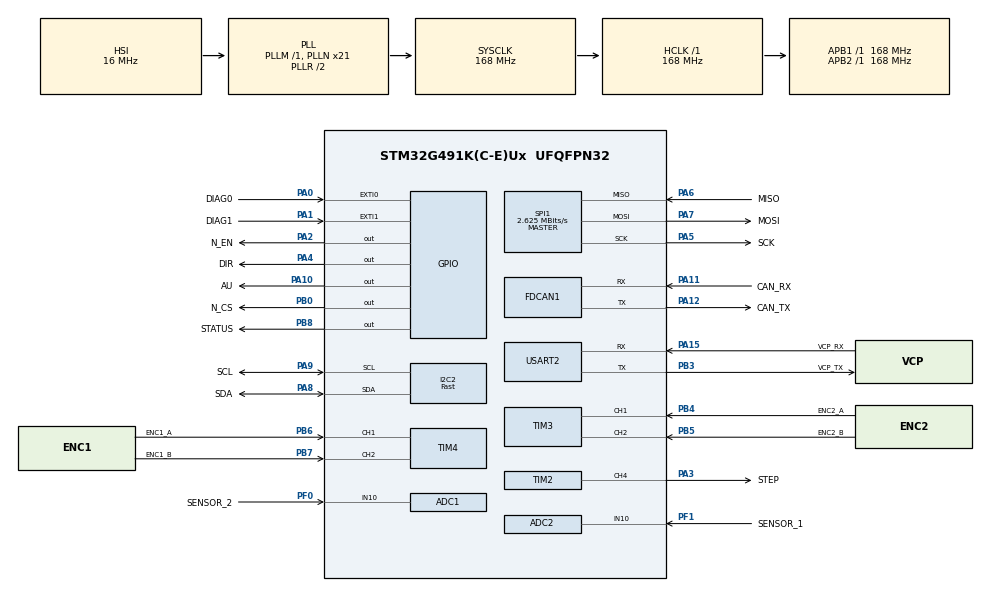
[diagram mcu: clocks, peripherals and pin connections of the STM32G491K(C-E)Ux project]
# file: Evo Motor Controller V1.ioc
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ADC1.Channel-0\#ChannelRegularConversion=ADC_CHANNEL_10
ADC1.NbrOfConversionFlag=1
ADC1.OffsetNumber-0\#ChannelRegularConversion=ADC_OFFSET_NONE
ADC1.Rank-0\#ChannelRegularConversion=1
ADC1.SamplingTime-0\#ChannelRegularConversion=ADC_SAMPLETIME_2CYCLES_5
ADC1.master=1
ADC2.Channel-0\#ChannelRegularConversion=ADC_CHANNEL_10
ADC2.NbrOfConversionFlag=1
ADC2.OffsetNumber-0\#ChannelRegularConversion=ADC_OFFSET_NONE
ADC2.Rank-0\#ChannelRegularConversion=1
ADC2.SamplingTime-0\#ChannelRegularConversion=ADC_SAMPLETIME_2CYCLES_5
FDCAN1.CalculateBaudRateNominal=2100000
FDCAN1.CalculateTimeBitNominal=476
FDCAN1.CalculateTimeQuantumNominal=95.23809523809524
I2C2.I2C_Speed_Mode=I2C_Fast
I2C2.Timing=0x20B21E5A
Mcu.Family=STM32G4
Mcu.Name=STM32G491K(C-E)Ux
Mcu.Package=UFQFPN32
NVIC.I2C2_ER_IRQn=true\:0\:0\:false\:false\:true\:true\:true\:true
NVIC.I2C2_EV_IRQn=true\:0\:0\:false\:false\:true\:true\:true\:true
NVIC.PriorityGroup=NVIC_PRIORITYGROUP_4
PA0.GPIO_Label=DIAG0
PA0.Signal=GPXTI0
PA1.GPIO_Label=DIAG1
PA1.Signal=GPXTI1
PA10.GPIO_Label=AU
PA10.Signal=GPIO_Output
PA11.GPIO_Label=CAN_RX
PA11.Mode=FDCAN_Activate
PA11.Signal=FDCAN1_RX
PA12.GPIO_Label=CAN_TX
PA12.Mode=FDCAN_Activate
PA12.Signal=FDCAN1_TX
PA13.GPIO_Label=SWDIO
PA13.Mode=Serial_Wire
PA13.Signal=SYS_JTMS-SWDIO
PA14.GPIO_Label=SWCLK
PA14.Mode=Serial_Wire
PA14.Signal=SYS_JTCK-SWCLK
PA15.GPIO_Label=VCP_RX
PA15.Mode=Asynchronous
PA15.Signal=USART2_RX
PA2.GPIO_Label=N_EN
PA2.Signal=GPIO_Output
PA3.GPIO_Label=STEP
PA3.Signal=S_TIM2_CH4
PA4.GPIO_Label=DIR
PA4.Signal=GPIO_Output
PA5.GPIO_Label=SCK
PA5.Mode=Full_Duplex_Master
PA5.Signal=SPI1_SCK
PA6.GPIO_Label=MISO
PA6.Mode=Full_Duplex_Master
PA6.Signal=SPI1_MISO
PA7.GPIO_Label=MOSI
PA7.Mode=Full_Duplex_Master
PA7.Signal=SPI1_MOSI
PA8.GPIO_Label=SDA
PA8.Mode=I2C
PA8.Signal=I2C2_SDA
PA9.GPIO_Label=SCL
PA9.Mode=I2C
PA9.Signal=I2C2_SCL
PB0.GPIO_Label=N_CS
PB0.Signal=GPIO_Output
PB3.GPIO_Label=VCP_TX
PB3.Mode=Asynchronous
PB3.Signal=USART2_TX
PB4.GPIO_Label=ENC2_A
PB4.Signal=S_TIM3_CH1
PB5.GPIO_Label=ENC2_B
PB5.Signal=S_TIM3_CH2
PB6.GPIO_Label=ENC1_A
PB6.Signal=S_TIM4_CH1
PB7.GPIO_Label=ENC1_B
PB7.Signal=S_TIM4_CH2
PB8-BOOT0.GPIO_Label=STATUS
PB8-BOOT0.Signal=GPIO_Output
PF0-OSC_IN.GPIO_Label=SENSOR_2
PF0-OSC_IN.Mode=IN10-Single-Ended
PF0-OSC_IN.Signal=ADC1_IN10
PF1-OSC_OUT.GPIO_Label=SENSOR_1
PF1-OSC_OUT.Mode=IN10-Single-Ended
PF1-OSC_OUT.Signal=ADC2_IN10
ProjectManager.HeapSize=0x200
ProjectManager.StackSize=0x400
ProjectManager.TargetToolchain=STM32CubeIDE
RCC.ADC12Freq_Value=168000000
RCC.ADC345Freq_Value=168000000
RCC.AHBFreq_Value=168000000
RCC.APB1Freq_Value=168000000
RCC.APB1TimFreq_Value=168000000
RCC.APB2Freq_Value=168000000
RCC.APB2TimFreq_Value=168000000
RCC.CortexFreq_Value=168000000
RCC.EXTERNAL_CLOCK_VALUE=12288000
RCC.HCLKFreq_Value=168000000
RCC.HSE_VALUE=8000000
RCC.HSI48_VALUE=48000000
RCC.HSI_VALUE=16000000
RCC.LSE_VALUE=32768
RCC.PLLN=21
RCC.SYSCLKFreq_VALUE=168000000
RCC.SYSCLKSource=RCC_SYSCLKSOURCE_PLLCLK
RCC.VCOOutputFreq_Value=336000000
SH.S_TIM2_CH4.0=TIM2_CH4,PWM Generation4 CH4
SH.S_TIM3_CH1.0=TIM3_CH1,Encoder_Interface
SH.S_TIM3_CH2.0=TIM3_CH2,Encoder_Interface
SH.S_TIM4_CH1.0=TIM4_CH1,Encoder_Interface
SH.S_TIM4_CH2.0=TIM4_CH2,Encoder_Interface
SPI1.BaudRatePrescaler=SPI_BAUDRATEPRESCALER_64
SPI1.CLKPhase=SPI_PHASE_2EDGE
SPI1.CLKPolarity=SPI_POLARITY_HIGH
SPI1.CalculateBaudRate=2.625 MBits/s
SPI1.DataSize=SPI_DATASIZE_8BIT
SPI1.Direction=SPI_DIRECTION_2LINES
SPI1.Mode=SPI_MODE_MASTER
SPI1.VirtualType=VM_MASTER
TIM2.Channel-PWM\ Generation4\ CH4=TIM_CHANNEL_4
USART2.VirtualMode-Asynchronous=VM_ASYNC
VP_SYS_VS_DBSignals.Mode=DisableDeadBatterySignals
board=custom

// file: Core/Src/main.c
/* USER CODE BEGIN Header */
/**
  ******************************************************************************
  * @file           : main.c
  * @brief          : Main program body
  ******************************************************************************
  * @attention
  *
  * Copyright (c) 2025 STMicroelectronics.
  * All rights reserved.
  *
  * This software is licensed under terms that can be found in the LICENSE file
  * in the root directory of this software component.
  * If no LICENSE file comes with this software, it is provided AS-IS.
  *
  ******************************************************************************
  */
/* USER CODE END Header */
#include "main.h"

/* USER CODE BEGIN Includes */
#include <stdio.h>

#include "runtime.h"
/* USER CODE END Includes */

ADC_HandleTypeDef hadc1;
ADC_HandleTypeDef hadc2;

FDCAN_HandleTypeDef hfdcan1;

I2C_HandleTypeDef hi2c2;

SPI_HandleTypeDef hspi1;

TIM_HandleTypeDef htim2;
TIM_HandleTypeDef htim3;
TIM_HandleTypeDef htim4;

UART_HandleTypeDef huart2;

void SystemClock_Config(void);
static void MX_GPIO_Init(void);
static void MX_ADC1_Init(void);
static void MX_ADC2_Init(void);
static void MX_SPI1_Init(void);
static void MX_TIM2_Init(void);
static void MX_TIM4_Init(void);
static void MX_USART2_UART_Init(void);
static void MX_FDCAN1_Init(void);
static void MX_I2C2_Init(void);
static void MX_TIM3_Init(void);

/* USER CODE BEGIN 0 */
uint8_t __io_putchar(char ch){
	HAL_UART_Transmit(&huart2, (uint8_t*)&ch, 1, HAL_MAX_DELAY);
	return ch;
}
uint8_t __io_getchar(char ch){
    return HAL_UART_Transmit(&huart2, (uint8_t*)&ch, 1, HAL_MAX_DELAY);

}
/* USER CODE END 0 */

int main(void)
{

  /* MCU Configuration--------------------------------------------------------*/

  /* Reset of all peripherals, Initializes the Flash interface and the Systick. */
  HAL_Init();

  /* Configure the system clock */
  SystemClock_Config();

  /* Initialize all configured peripherals */
  MX_GPIO_Init();
  MX_ADC1_Init();
  MX_ADC2_Init();
  MX_SPI1_Init();
  MX_TIM2_Init();
  MX_TIM4_Init();
  MX_USART2_UART_Init();
  MX_FDCAN1_Init();
  MX_I2C2_Init();
  MX_TIM3_Init();
  /* USER CODE BEGIN 2 */
  printf("HAL init done ... \n");
  setup();
  printf("User init done ... \n");
  /* USER CODE END 2 */

  /* Infinite loop */
  /* USER CODE BEGIN WHILE */
  while (1)
  {
	  loop();
    /* USER CODE END WHILE */

  }
}

void SystemClock_Config(void)
{
  RCC_OscInitTypeDef RCC_OscInitStruct = {0};
  RCC_ClkInitTypeDef RCC_ClkInitStruct = {0};

  /** Configure the main internal regulator output voltage
  */
  HAL_PWREx_ControlVoltageScaling(PWR_REGULATOR_VOLTAGE_SCALE1_BOOST);

  /** Initializes the RCC Oscillators according to the specified parameters
  * in the RCC_OscInitTypeDef structure.
  */
  RCC_OscInitStruct.OscillatorType = RCC_OSCILLATORTYPE_HSI;
  RCC_OscInitStruct.HSIState = RCC_HSI_ON;
  RCC_OscInitStruct.HSICalibrationValue = RCC_HSICALIBRATION_DEFAULT;
  RCC_OscInitStruct.PLL.PLLState = RCC_PLL_ON;
  RCC_OscInitStruct.PLL.PLLSource = RCC_PLLSOURCE_HSI;
  RCC_OscInitStruct.PLL.PLLM = RCC_PLLM_DIV1;
  RCC_OscInitStruct.PLL.PLLN = 21;
  RCC_OscInitStruct.PLL.PLLP = RCC_PLLP_DIV2;
  RCC_OscInitStruct.PLL.PLLQ = RCC_PLLQ_DIV2;
  RCC_OscInitStruct.PLL.PLLR = RCC_PLLR_DIV2;
  if (HAL_RCC_OscConfig(&RCC_OscInitStruct) != HAL_OK)
  {
    Error_Handler();
  }

  /** Initializes the CPU, AHB and APB buses clocks
  */
  RCC_ClkInitStruct.ClockType = RCC_CLOCKTYPE_HCLK|RCC_CLOCKTYPE_SYSCLK
                              |RCC_CLOCKTYPE_PCLK1|RCC_CLOCKTYPE_PCLK2;
  RCC_ClkInitStruct.SYSCLKSource = RCC_SYSCLKSOURCE_PLLCLK;
  RCC_ClkInitStruct.AHBCLKDivider = RCC_SYSCLK_DIV1;
  RCC_ClkInitStruct.APB1CLKDivider = RCC_HCLK_DIV1;
  RCC_ClkInitStruct.APB2CLKDivider = RCC_HCLK_DIV1;

  if (HAL_RCC_ClockConfig(&RCC_ClkInitStruct, FLASH_LATENCY_4) != HAL_OK)
  {
    Error_Handler();
  }
}

static void MX_ADC1_Init(void)
{

  ADC_MultiModeTypeDef multimode = {0};
  ADC_ChannelConfTypeDef sConfig = {0};

  /** Common config
  */
  hadc1.Instance = ADC1;
  hadc1.Init.ClockPrescaler = ADC_CLOCK_SYNC_PCLK_DIV4;
  hadc1.Init.Resolution = ADC_RESOLUTION_12B;
  hadc1.Init.DataAlign = ADC_DATAALIGN_RIGHT;
  hadc1.Init.GainCompensation = 0;
  hadc1.Init.ScanConvMode = ADC_SCAN_DISABLE;
  hadc1.Init.EOCSelection = ADC_EOC_SINGLE_CONV;
  hadc1.Init.LowPowerAutoWait = DISABLE;
  hadc1.Init.ContinuousConvMode = DISABLE;
  hadc1.Init.NbrOfConversion = 1;
  hadc1.Init.DiscontinuousConvMode = DISABLE;
  hadc1.Init.ExternalTrigConv = ADC_SOFTWARE_START;
  hadc1.Init.ExternalTrigConvEdge = ADC_EXTERNALTRIGCONVEDGE_NONE;
  hadc1.Init.DMAContinuousRequests = DISABLE;
  hadc1.Init.Overrun = ADC_OVR_DATA_PRESERVED;
  hadc1.Init.OversamplingMode = DISABLE;
  if (HAL_ADC_Init(&hadc1) != HAL_OK)
  {
    Error_Handler();
  }

  /** Configure the ADC multi-mode
  */
  multimode.Mode = ADC_MODE_INDEPENDENT;
  if (HAL_ADCEx_MultiModeConfigChannel(&hadc1, &multimode) != HAL_OK)
  {
    Error_Handler();
  }

  /** Configure Regular Channel
  */
  sConfig.Channel = ADC_CHANNEL_10;
  sConfig.Rank = ADC_REGULAR_RANK_1;
  sConfig.SamplingTime = ADC_SAMPLETIME_2CYCLES_5;
  sConfig.SingleDiff = ADC_SINGLE_ENDED;
  sConfig.OffsetNumber = ADC_OFFSET_NONE;
  sConfig.Offset = 0;
  if (HAL_ADC_ConfigChannel(&hadc1, &sConfig) != HAL_OK)
  {
    Error_Handler();
  }

}

static void MX_ADC2_Init(void)
{

  ADC_ChannelConfTypeDef sConfig = {0};

  /** Common config
  */
  hadc2.Instance = ADC2;
  hadc2.Init.ClockPrescaler = ADC_CLOCK_SYNC_PCLK_DIV4;
  hadc2.Init.Resolution = ADC_RESOLUTION_12B;
  hadc2.Init.DataAlign = ADC_DATAALIGN_RIGHT;
  hadc2.Init.GainCompensation = 0;
  hadc2.Init.ScanConvMode = ADC_SCAN_DISABLE;
  hadc2.Init.EOCSelection = ADC_EOC_SINGLE_CONV;
  hadc2.Init.LowPowerAutoWait = DISABLE;
  hadc2.Init.ContinuousConvMode = DISABLE;
  hadc2.Init.NbrOfConversion = 1;
  hadc2.Init.DiscontinuousConvMode = DISABLE;
  hadc2.Init.ExternalTrigConv = ADC_SOFTWARE_START;
  hadc2.Init.ExternalTrigConvEdge = ADC_EXTERNALTRIGCONVEDGE_NONE;
  hadc2.Init.DMAContinuousRequests = DISABLE;
  hadc2.Init.Overrun = ADC_OVR_DATA_PRESERVED;
  hadc2.Init.OversamplingMode = DISABLE;
  if (HAL_ADC_Init(&hadc2) != HAL_OK)
  {
    Error_Handler();
  }

  /** Configure Regular Channel
  */
  sConfig.Channel = ADC_CHANNEL_10;
  sConfig.Rank = ADC_REGULAR_RANK_1;
  sConfig.SamplingTime = ADC_SAMPLETIME_2CYCLES_5;
  sConfig.SingleDiff = ADC_SINGLE_ENDED;
  sConfig.OffsetNumber = ADC_OFFSET_NONE;
  sConfig.Offset = 0;
  if (HAL_ADC_ConfigChannel(&hadc2, &sConfig) != HAL_OK)
  {
    Error_Handler();
  }

}

static void MX_FDCAN1_Init(void)
{

  hfdcan1.Instance = FDCAN1;
  hfdcan1.Init.ClockDivider = FDCAN_CLOCK_DIV1;
  hfdcan1.Init.FrameFormat = FDCAN_FRAME_CLASSIC;
  hfdcan1.Init.Mode = FDCAN_MODE_NORMAL;
  hfdcan1.Init.AutoRetransmission = DISABLE;
  hfdcan1.Init.TransmitPause = DISABLE;
  hfdcan1.Init.ProtocolException = DISABLE;
  hfdcan1.Init.NominalPrescaler = 16;
  hfdcan1.Init.NominalSyncJumpWidth = 1;
  hfdcan1.Init.NominalTimeSeg1 = 2;
  hfdcan1.Init.NominalTimeSeg2 = 2;
  hfdcan1.Init.DataPrescaler = 1;
  hfdcan1.Init.DataSyncJumpWidth = 1;
  hfdcan1.Init.DataTimeSeg1 = 1;
  hfdcan1.Init.DataTimeSeg2 = 1;
  hfdcan1.Init.StdFiltersNbr = 0;
  hfdcan1.Init.ExtFiltersNbr = 0;
  hfdcan1.Init.TxFifoQueueMode = FDCAN_TX_FIFO_OPERATION;
  if (HAL_FDCAN_Init(&hfdcan1) != HAL_OK)
  {
    Error_Handler();
  }

}

static void MX_I2C2_Init(void)
{

  hi2c2.Instance = I2C2;
  hi2c2.Init.Timing = 0x20B21E5A;
  hi2c2.Init.OwnAddress1 = 0;
  hi2c2.Init.AddressingMode = I2C_ADDRESSINGMODE_7BIT;
  hi2c2.Init.DualAddressMode = I2C_DUALADDRESS_DISABLE;
  hi2c2.Init.OwnAddress2 = 0;
  hi2c2.Init.OwnAddress2Masks = I2C_OA2_NOMASK;
  hi2c2.Init.GeneralCallMode = I2C_GENERALCALL_DISABLE;
  hi2c2.Init.NoStretchMode = I2C_NOSTRETCH_DISABLE;
  if (HAL_I2C_Init(&hi2c2) != HAL_OK)
  {
    Error_Handler();
  }

  /** Configure Analogue filter
  */
  if (HAL_I2CEx_ConfigAnalogFilter(&hi2c2, I2C_ANALOGFILTER_ENABLE) != HAL_OK)
  {
    Error_Handler();
  }

  /** Configure Digital filter
  */
  if (HAL_I2CEx_ConfigDigitalFilter(&hi2c2, 0) != HAL_OK)
  {
    Error_Handler();
  }

}

static void MX_SPI1_Init(void)
{

  /* SPI1 parameter configuration*/
  hspi1.Instance = SPI1;
  hspi1.Init.Mode = SPI_MODE_MASTER;
  hspi1.Init.Direction = SPI_DIRECTION_2LINES;
  hspi1.Init.DataSize = SPI_DATASIZE_8BIT;
  hspi1.Init.CLKPolarity = SPI_POLARITY_HIGH;
  hspi1.Init.CLKPhase = SPI_PHASE_2EDGE;
  hspi1.Init.NSS = SPI_NSS_SOFT;
  hspi1.Init.BaudRatePrescaler = SPI_BAUDRATEPRESCALER_64;
  hspi1.Init.FirstBit = SPI_FIRSTBIT_MSB;
  hspi1.Init.TIMode = SPI_TIMODE_DISABLE;
  hspi1.Init.CRCCalculation = SPI_CRCCALCULATION_DISABLE;
  hspi1.Init.CRCPolynomial = 7;
  hspi1.Init.CRCLength = SPI_CRC_LENGTH_DATASIZE;
  hspi1.Init.NSSPMode = SPI_NSS_PULSE_DISABLE;
  if (HAL_SPI_Init(&hspi1) != HAL_OK)
  {
    Error_Handler();
  }

}

static void MX_TIM2_Init(void)
{

  TIM_MasterConfigTypeDef sMasterConfig = {0};
  TIM_OC_InitTypeDef sConfigOC = {0};

  htim2.Instance = TIM2;
  htim2.Init.Prescaler = 0;
  htim2.Init.CounterMode = TIM_COUNTERMODE_UP;
  htim2.Init.Period = 4294967295;
  htim2.Init.ClockDivision = TIM_CLOCKDIVISION_DIV1;
  htim2.Init.AutoReloadPreload = TIM_AUTORELOAD_PRELOAD_DISABLE;
  if (HAL_TIM_PWM_Init(&htim2) != HAL_OK)
  {
    Error_Handler();
  }
  sMasterConfig.MasterOutputTrigger = TIM_TRGO_RESET;
  sMasterConfig.MasterSlaveMode = TIM_MASTERSLAVEMODE_DISABLE;
  if (HAL_TIMEx_MasterConfigSynchronization(&htim2, &sMasterConfig) != HAL_OK)
  {
    Error_Handler();
  }
  sConfigOC.OCMode = TIM_OCMODE_PWM1;
  sConfigOC.Pulse = 0;
  sConfigOC.OCPolarity = TIM_OCPOLARITY_HIGH;
  sConfigOC.OCFastMode = TIM_OCFAST_DISABLE;
  if (HAL_TIM_PWM_ConfigChannel(&htim2, &sConfigOC, TIM_CHANNEL_4) != HAL_OK)
  {
    Error_Handler();
  }
  HAL_TIM_MspPostInit(&htim2);

}

static void MX_TIM3_Init(void)
{

  TIM_Encoder_InitTypeDef sConfig = {0};
  TIM_MasterConfigTypeDef sMasterConfig = {0};

  htim3.Instance = TIM3;
  htim3.Init.Prescaler = 0;
  htim3.Init.CounterMode = TIM_COUNTERMODE_UP;
  htim3.Init.Period = 65535;
  htim3.Init.ClockDivision = TIM_CLOCKDIVISION_DIV1;
  htim3.Init.AutoReloadPreload = TIM_AUTORELOAD_PRELOAD_DISABLE;
  sConfig.EncoderMode = TIM_ENCODERMODE_TI1;
  sConfig.IC1Polarity = TIM_ICPOLARITY_RISING;
  sConfig.IC1Selection = TIM_ICSELECTION_DIRECTTI;
  sConfig.IC1Prescaler = TIM_ICPSC_DIV1;
  sConfig.IC1Filter = 0;
  sConfig.IC2Polarity = TIM_ICPOLARITY_RISING;
  sConfig.IC2Selection = TIM_ICSELECTION_DIRECTTI;
  sConfig.IC2Prescaler = TIM_ICPSC_DIV1;
  sConfig.IC2Filter = 0;
  if (HAL_TIM_Encoder_Init(&htim3, &sConfig) != HAL_OK)
  {
    Error_Handler();
  }
  sMasterConfig.MasterOutputTrigger = TIM_TRGO_RESET;
  sMasterConfig.MasterSlaveMode = TIM_MASTERSLAVEMODE_DISABLE;
  if (HAL_TIMEx_MasterConfigSynchronization(&htim3, &sMasterConfig) != HAL_OK)
  {
    Error_Handler();
  }

}

static void MX_TIM4_Init(void)
{

  TIM_Encoder_InitTypeDef sConfig = {0};
  TIM_MasterConfigTypeDef sMasterConfig = {0};

  htim4.Instance = TIM4;
  htim4.Init.Prescaler = 0;
  htim4.Init.CounterMode = TIM_COUNTERMODE_UP;
  htim4.Init.Period = 65535;
  htim4.Init.ClockDivision = TIM_CLOCKDIVISION_DIV1;
  htim4.Init.AutoReloadPreload = TIM_AUTORELOAD_PRELOAD_DISABLE;
  sConfig.EncoderMode = TIM_ENCODERMODE_TI1;
  sConfig.IC1Polarity = TIM_ICPOLARITY_RISING;
  sConfig.IC1Selection = TIM_ICSELECTION_DIRECTTI;
  sConfig.IC1Prescaler = TIM_ICPSC_DIV1;
  sConfig.IC1Filter = 0;
  sConfig.IC2Polarity = TIM_ICPOLARITY_RISING;
  sConfig.IC2Selection = TIM_ICSELECTION_DIRECTTI;
  sConfig.IC2Prescaler = TIM_ICPSC_DIV1;
  sConfig.IC2Filter = 0;
  if (HAL_TIM_Encoder_Init(&htim4, &sConfig) != HAL_OK)
  {
    Error_Handler();
  }
  sMasterConfig.MasterOutputTrigger = TIM_TRGO_RESET;
  sMasterConfig.MasterSlaveMode = TIM_MASTERSLAVEMODE_DISABLE;
  if (HAL_TIMEx_MasterConfigSynchronization(&htim4, &sMasterConfig) != HAL_OK)
  {
    Error_Handler();
  }

}

static void MX_USART2_UART_Init(void)
{

  huart2.Instance = USART2;
  huart2.Init.BaudRate = 115200;
  huart2.Init.WordLength = UART_WORDLENGTH_8B;
  huart2.Init.StopBits = UART_STOPBITS_1;
  huart2.Init.Parity = UART_PARITY_NONE;
  huart2.Init.Mode = UART_MODE_TX_RX;
  huart2.Init.HwFlowCtl = UART_HWCONTROL_NONE;
  huart2.Init.OverSampling = UART_OVERSAMPLING_16;
  huart2.Init.OneBitSampling = UART_ONE_BIT_SAMPLE_DISABLE;
  huart2.Init.ClockPrescaler = UART_PRESCALER_DIV1;
  huart2.AdvancedInit.AdvFeatureInit = UART_ADVFEATURE_NO_INIT;
  if (HAL_UART_Init(&huart2) != HAL_OK)
  {
    Error_Handler();
  }
  if (HAL_UARTEx_SetTxFifoThreshold(&huart2, UART_TXFIFO_THRESHOLD_1_8) != HAL_OK)
  {
    Error_Handler();
  }
  if (HAL_UARTEx_SetRxFifoThreshold(&huart2, UART_RXFIFO_THRESHOLD_1_8) != HAL_OK)
  {
    Error_Handler();
  }
  if (HAL_UARTEx_DisableFifoMode(&huart2) != HAL_OK)
  {
    Error_Handler();
  }

}

static void MX_GPIO_Init(void)
{
  GPIO_InitTypeDef GPIO_InitStruct = {0};

  /* GPIO Ports Clock Enable */
  __HAL_RCC_GPIOF_CLK_ENABLE();
  __HAL_RCC_GPIOA_CLK_ENABLE();
  __HAL_RCC_GPIOB_CLK_ENABLE();

  /*Configure GPIO pin Output Level */
  HAL_GPIO_WritePin(GPIOA, N_EN_Pin|DIR_Pin|AU_Pin, GPIO_PIN_RESET);

  /*Configure GPIO pin Output Level */
  HAL_GPIO_WritePin(GPIOB, N_CS_Pin|STATUS_Pin, GPIO_PIN_RESET);

  /*Configure GPIO pins : DIAG0_Pin DIAG1_Pin */
  GPIO_InitStruct.Pin = DIAG0_Pin|DIAG1_Pin;
  GPIO_InitStruct.Mode = GPIO_MODE_IT_RISING;
  GPIO_InitStruct.Pull = GPIO_NOPULL;
  HAL_GPIO_Init(GPIOA, &GPIO_InitStruct);

  /*Configure GPIO pins : N_EN_Pin DIR_Pin AU_Pin */
  GPIO_InitStruct.Pin = N_EN_Pin|DIR_Pin|AU_Pin;
  GPIO_InitStruct.Mode = GPIO_MODE_OUTPUT_PP;
  GPIO_InitStruct.Pull = GPIO_NOPULL;
  GPIO_InitStruct.Speed = GPIO_SPEED_FREQ_LOW;
  HAL_GPIO_Init(GPIOA, &GPIO_InitStruct);

  /*Configure GPIO pins : N_CS_Pin STATUS_Pin */
  GPIO_InitStruct.Pin = N_CS_Pin|STATUS_Pin;
  GPIO_InitStruct.Mode = GPIO_MODE_OUTPUT_PP;
  GPIO_InitStruct.Pull = GPIO_NOPULL;
  GPIO_InitStruct.Speed = GPIO_SPEED_FREQ_LOW;
  HAL_GPIO_Init(GPIOB, &GPIO_InitStruct);

}

void Error_Handler(void)
{
  __disable_irq();
  while (1)
  {
  }
}
